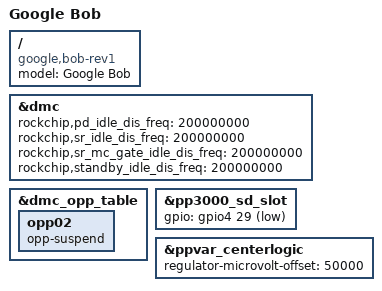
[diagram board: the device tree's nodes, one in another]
/*
 * Google Gru-Bob Rev 0~1 board device tree source
 *
 * Copyright 2016 Google, Inc
 *
 * This file is dual-licensed: you can use it either under the terms
 * of the GPL or the X11 license, at your option. Note that this dual
 * licensing only applies to this file, and not this project as a
 * whole.
 *
 *  a) This file is free software; you can redistribute it and/or
 *     modify it under the terms of the GNU General Public License as
 *     published by the Free Software Foundation; either version 2 of the
 *     License, or (at your option) any later version.
 *
 *     This file is distributed in the hope that it will be useful,
 *     but WITHOUT ANY WARRANTY; without even the implied warranty of
 *     MERCHANTABILITY or FITNESS FOR A PARTICULAR PURPOSE.  See the
 *     GNU General Public License for more details.
 *
 *  Or, alternatively,
 *
 *  b) Permission is hereby granted, free of charge, to any person
 *     obtaining a copy of this software and associated documentation
 *     files (the "Software"), to deal in the Software without
 *     restriction, including without limitation the rights to use,
 *     copy, modify, merge, publish, distribute, sublicense, and/or
 *     sell copies of the Software, and to permit persons to whom the
 *     Software is furnished to do so, subject to the following
 *     conditions:
 *
 *     The above copyright notice and this permission notice shall be
 *     included in all copies or substantial portions of the Software.
 *
 *     THE SOFTWARE IS PROVIDED "AS IS", WITHOUT WARRANTY OF ANY KIND,
 *     EXPRESS OR IMPLIED, INCLUDING BUT NOT LIMITED TO THE WARRANTIES
 *     OF MERCHANTABILITY, FITNESS FOR A PARTICULAR PURPOSE AND
 *     NONINFRINGEMENT. IN NO EVENT SHALL THE AUTHORS OR COPYRIGHT
 *     HOLDERS BE LIABLE FOR ANY CLAIM, DAMAGES OR OTHER LIABILITY,
 *     WHETHER IN AN ACTION OF CONTRACT, TORT OR OTHERWISE, ARISING
 *     FROM, OUT OF OR IN CONNECTION WITH THE SOFTWARE OR THE USE OR
 *     OTHER DEALINGS IN THE SOFTWARE.
 */

/dts-v1/;
#include "rk3399-gru-bob.dtsi"

/ {
	model = "Google Bob";
	compatible = "google,bob-rev1", "google,bob-rev0",
		     "google,bob", "google,gru", "rockchip,rk3399";
};

/*
 * HACK: Disabling the ddr auto power down on bob board, since the caused by
 * the ripple of hardware.
 */
&dmc {
	rockchip,pd_idle_dis_freq = <200000000>;
	rockchip,sr_idle_dis_freq = <200000000>;
	rockchip,sr_mc_gate_idle_dis_freq = <200000000>;
	rockchip,standby_idle_dis_freq = <200000000>;
};

&dmc_opp_table {
	opp02 {
		opp-suspend;
	};

	/delete-node/ opp03;
};

&pp3000_sd_slot {
	/delete-property/ enable-active-high;
	gpio = <&gpio4 29 GPIO_ACTIVE_LOW>;
};

/*
 * HACK for -rev0~1 to bump up voltage
 *
　* There's some extra voltage drop on early revs of bob due to board layout
 * problems. On -rev0~1 we're almost there, so only 50 mV for center-logic.
 *
 * NOTE: The 'regulator-microvolt-offset' is not a terribly well-tested and
 * has some quirks (like I think it doesn't necessarily validate constraints
 * properly?), but seems to work and seems better than hardcoding every
 * operating point everywhere.
 */
&ppvar_centerlogic {
	regulator-microvolt-offset = <50000>;
};
